# nrf7120_enga_flpr register map
Vendor: Nordic Semiconductor; Series: nrf71; File version: 1
Registers are 32-bit, read-write, reset 0x0 unless marked. A register's access mark holds for its fields unless they carry their own. Offsets are from the block's base; [hi:lo] are bit positions; lines under a group give offsets from that group; 'fields as' and 'values as' point back to an identical list.

## GLOBAL_GLITCHDET_S — Voltage glitch detectors
Base 0x50111000
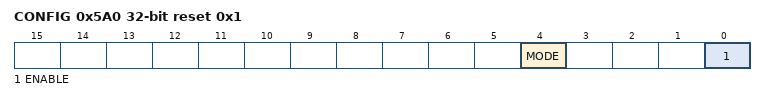
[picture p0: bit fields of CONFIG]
0x5A0 CONFIG reset 0x1 — Configuration for glitch detector
  [4] MODE — Glitch detector mode
    0=High pass filter mode; 1=Cap divider mode
  [0] ENABLE — Enable glitch detector
    0=Disable glitch detector; 1=Enable glitch detector

## GLOBAL_OSCILLATORS_NS — Oscillator control 0
Base 0x40120000
Same registers: GLOBAL_OSCILLATORS_S 0x50120000
0x800 PLL group — Oscillator control
  0x00 FREQ reset 0x4 — Set speed of MCU power domain, including CPU
    [2:0] FREQ — Select CPU speed
      0=CK256M (256 MHz); 2=CK128M (128 MHz); 4=CK64M (64 MHz); 6=CK43M (42.667 MHz)
  0x04 CURRENTFREQ ro reset 0x4 — Current speed of MCU power domain, including CPU
    [2:0] CURRENTFREQ — Select CPU speed
      values as PLL.FREQ.FREQ

## GLOBAL_REGULATORS_NS — Voltage regulators 0
Base 0x40120000; alternate view of GLOBAL_OSCILLATORS_NS
Same registers: GLOBAL_REGULATORS_S 0x50120000 (alternate view of GLOBAL_OSCILLATORS_S)
0x500 SYSTEMOFF wo
  [0] SYSTEMOFF — Enable System OFF mode
    1=Enter (Enable System OFF mode)

## GLOBAL_VREGUSB_NS — VREGUSB peripheral 0
Base 0x40121000
Same registers: GLOBAL_VREGUSB_S 0x50121000
0x00 TASKS_START wo — Request power up of USB PM
  [0] TASKS_START
    1=Trigger task
0x04 TASKS_STOP wo — Stop requesting power up of USB PM
  [0] TASKS_STOP
    1=Trigger task
0x104 EVENTS_VBUSDETECTED — VBUS detected
  [0] EVENTS_VBUSDETECTED
    0=NotGenerated (Event not generated); 1=Generated (Event generated)
0x108 EVENTS_SETTLED0V8 — 0V8 settled
  [0] EVENTS_SETTLED0V8
    values as EVENTS_VBUSDETECTED.EVENTS_VBUSDETECTED
0x10C EVENTS_SETTLED3V3 — 3V3 settled
  [0] EVENTS_SETTLED3V3
    values as EVENTS_VBUSDETECTED.EVENTS_VBUSDETECTED
0x110 EVENTS_VBUSREMOVED — VBUS removed
  [0] EVENTS_VBUSREMOVED
    values as EVENTS_VBUSDETECTED.EVENTS_VBUSDETECTED
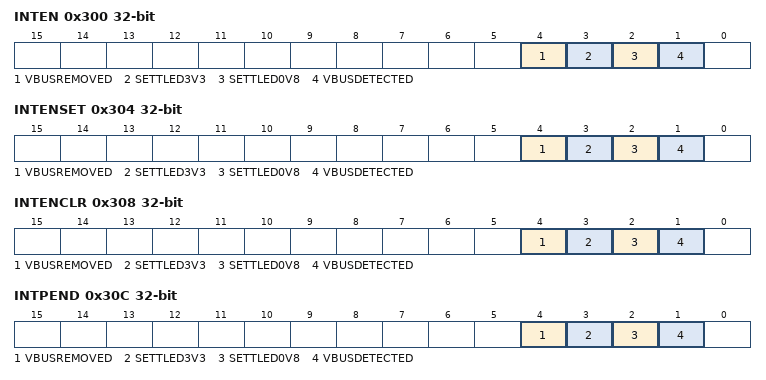
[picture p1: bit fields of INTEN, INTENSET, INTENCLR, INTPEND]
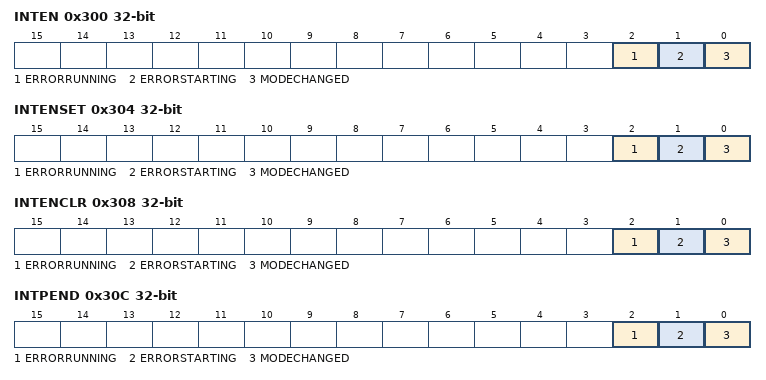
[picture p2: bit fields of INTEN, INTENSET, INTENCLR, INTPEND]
0x300 INTEN — Enable or disable interrupt
  [all] fields
    0=Disabled; 1=Enabled
  [4] VBUSREMOVED — Enable or disable interrupt for event VBUSREMOVED
  [3] SETTLED3V3 — Enable or disable interrupt for event SETTLED3V3
  [2] SETTLED0V8 — Enable or disable interrupt for event SETTLED0V8
  [1] VBUSDETECTED — Enable or disable interrupt for event VBUSDETECTED
0x304 INTENSET — Enable interrupt
  [all] fields
    on read: 0=Disabled (Read: Disabled); 1=Enabled (Read: Enabled) | on write: 1=Set (Enable)
  [4] VBUSREMOVED — Write '1' to enable interrupt for event VBUSREMOVED
  [3] SETTLED3V3 — Write '1' to enable interrupt for event SETTLED3V3
  [2] SETTLED0V8 — Write '1' to enable interrupt for event SETTLED0V8
  [1] VBUSDETECTED — Write '1' to enable interrupt for event VBUSDETECTED
0x308 INTENCLR — Disable interrupt
  [all] fields
    on read: 0=Disabled (Read: Disabled); 1=Enabled (Read: Enabled) | on write: 1=Clear (Disable)
  [4] VBUSREMOVED — Write '1' to disable interrupt for event VBUSREMOVED
  [3] SETTLED3V3 — Write '1' to disable interrupt for event SETTLED3V3
  [2] SETTLED0V8 — Write '1' to disable interrupt for event SETTLED0V8
  [1] VBUSDETECTED — Write '1' to disable interrupt for event VBUSDETECTED
0x30C INTPEND ro — Pending interrupts
  [all] fields
    on read: 0=NotPending (Read: Not pending); 1=Pending (Read: Pending)
  [4] VBUSREMOVED — Read pending status of interrupt for event VBUSREMOVED
  [3] SETTLED3V3 — Read pending status of interrupt for event SETTLED3V3
  [2] SETTLED0V8 — Read pending status of interrupt for event SETTLED0V8
  [1] VBUSDETECTED — Read pending status of interrupt for event VBUSDETECTED

## GLOBAL_LFXO_NS — LFXO peripheral 0
Base 0x40122000
Same registers: GLOBAL_LFXO_S 0x50122000
0x100 EVENTS_MODECHANGED — LFXO mode changed
  [0] EVENTS_MODECHANGED
    0=NotGenerated (Event not generated); 1=Generated (Event generated)
0x104 EVENTS_ERRORSTARTING — Error while starting the LFXO in PIERCE mode
  [0] EVENTS_ERRORSTARTING
    values as EVENTS_MODECHANGED.EVENTS_MODECHANGED
0x108 EVENTS_ERRORRUNNING — Error detected while LFXO was running
  [0] EVENTS_ERRORRUNNING
    values as EVENTS_MODECHANGED.EVENTS_MODECHANGED
0x300 INTEN — Enable or disable interrupt
  [all] fields
    0=Disabled; 1=Enabled
  [2] ERRORRUNNING — Enable or disable interrupt for event ERRORRUNNING
  [1] ERRORSTARTING — Enable or disable interrupt for event ERRORSTARTING
  [0] MODECHANGED — Enable or disable interrupt for event MODECHANGED
0x304 INTENSET — Enable interrupt
  [all] fields
    on read: 0=Disabled (Read: Disabled); 1=Enabled (Read: Enabled) | on write: 1=Set (Enable)
  [2] ERRORRUNNING — Write '1' to enable interrupt for event ERRORRUNNING
  [1] ERRORSTARTING — Write '1' to enable interrupt for event ERRORSTARTING
  [0] MODECHANGED — Write '1' to enable interrupt for event MODECHANGED
0x308 INTENCLR — Disable interrupt
  [all] fields
    on read: 0=Disabled (Read: Disabled); 1=Enabled (Read: Enabled) | on write: 1=Clear (Disable)
  [2] ERRORRUNNING — Write '1' to disable interrupt for event ERRORRUNNING
  [1] ERRORSTARTING — Write '1' to disable interrupt for event ERRORSTARTING
  [0] MODECHANGED — Write '1' to disable interrupt for event MODECHANGED
0x30C INTPEND ro — Pending interrupts
  [all] fields
    on read: 0=NotPending (Read: Not pending); 1=Pending (Read: Pending)
  [2] ERRORRUNNING — Read pending status of interrupt for event ERRORRUNNING
  [1] ERRORSTARTING — Read pending status of interrupt for event ERRORSTARTING
  [0] MODECHANGED — Read pending status of interrupt for event MODECHANGED
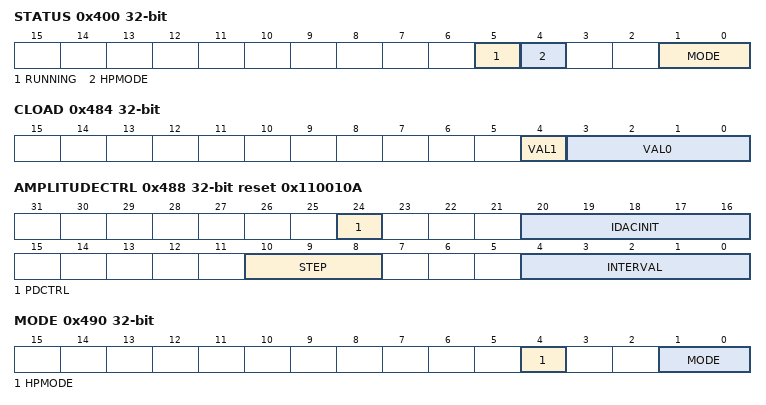
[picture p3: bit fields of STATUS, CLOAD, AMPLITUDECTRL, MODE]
0x400 STATUS ro — LFXO status
  [5] RUNNING — LFXO running status
    0=NotRunning (LFXO not running); 1=Running (LFXO running)
  [4] HPMODE — High performance mode
    0=Disabled (High performance mode disabled); 1=Enabled (High performance mode enabled)
  [1:0] MODE — Current mode
    0=Pierce mode; 1=PIXO mode; 2=External sine wave clock; 3=External square wave clock
0x484 CLOAD — Internal capacitive load
  [4] VAL1 — Capacitive load value
  [3:0] VAL0 — Capacitive load value
0x488 AMPLITUDECTRL reset 0x110010A — Amplitude control
  [24] PDCTRL — Peak detector control
    0=Disabled (Peak detector disabled); 1=Enabled (Peak detector enabled)
  [20:16] IDACINIT — Initial IDAC code for the pierce oscillator
  [10:8] STEP — Step to adjust the IDAC when the peak detector triggers
  [4:0] INTERVAL — Amplitude check interval
0x48C PWRUPCTRL — Power up control
  [1:0] CTRL
    0=Automatically handled by the peripheral; 1=PowerUp; 2=PowerDown
0x490 MODE — LFXO mode
  [4] HPMODE — High performance mode
    0=Disabled (Disable high performance mode); 1=Enabled (Enable high performance mode)
  [1:0] MODE
    values as STATUS.MODE
